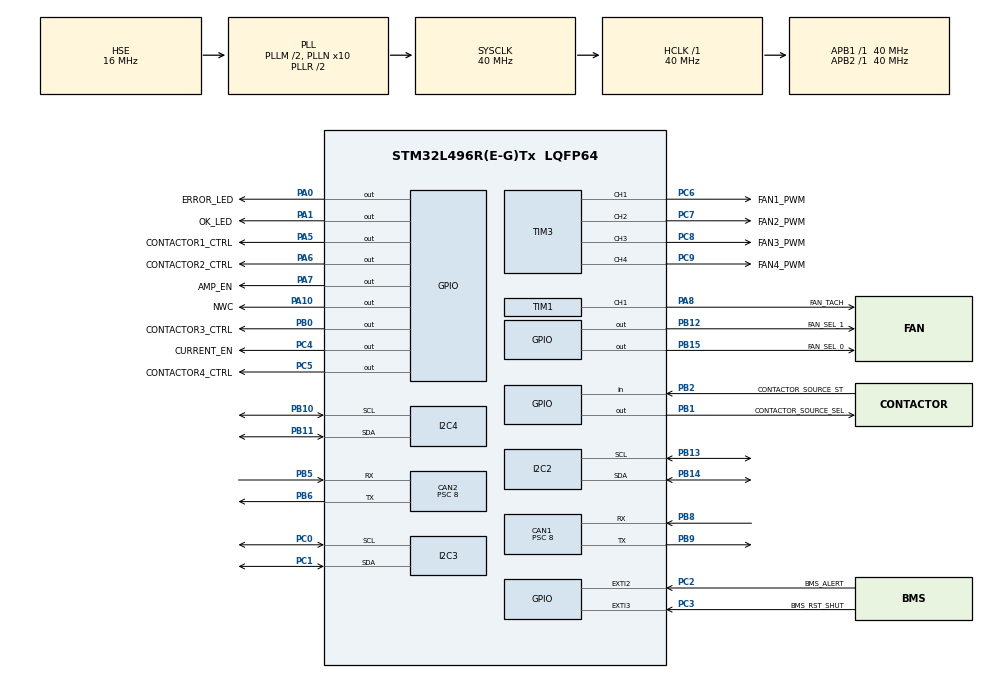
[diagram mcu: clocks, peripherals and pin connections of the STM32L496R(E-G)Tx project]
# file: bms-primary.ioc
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CAN1.BS1=CAN_BS1_8TQ
CAN1.BS2=CAN_BS2_1TQ
CAN1.CalculateBaudRate=500000
CAN1.CalculateTimeBit=2000
CAN1.CalculateTimeQuantum=200.0
CAN1.Prescaler=8
CAN2.BS1=CAN_BS1_8TQ
CAN2.BS2=CAN_BS2_1TQ
CAN2.CalculateBaudRate=500000
CAN2.CalculateTimeBit=2000
CAN2.CalculateTimeQuantum=200.0
CAN2.Prescaler=8
FREERTOS.Tasks01=defaultTask,24,128,StartDefaultTask,Default,NULL,Dynamic,NULL,NULL
I2C2.Timing=0x00909BEB
I2C3.Timing=0x00D09BE3
I2C4.Timing=0x00909BEB
IWDG.Prescaler=IWDG_PRESCALER_256
IWDG.Reload=125
IWDG.Window=125
Mcu.Family=STM32L4
Mcu.Name=STM32L496R(E-G)Tx
Mcu.Package=LQFP64
NVIC.CAN1_RX0_IRQn=true\:5\:0\:false\:false\:true\:true\:true\:true\:true
NVIC.CAN1_RX1_IRQn=true\:5\:0\:false\:false\:true\:true\:true\:true\:true
NVIC.CAN2_RX0_IRQn=true\:5\:0\:false\:false\:true\:true\:true\:true\:true
NVIC.CAN2_RX1_IRQn=true\:5\:0\:false\:false\:true\:true\:true\:true\:true
NVIC.PriorityGroup=NVIC_PRIORITYGROUP_4
NVIC.TIM1_TRG_COM_TIM17_IRQn=true\:15\:0\:false\:false\:true\:false\:false\:true\:true
NVIC.TimeBase=TIM1_TRG_COM_TIM17_IRQn
NVIC.TimeBaseIP=TIM17
PA0.GPIO_Label=ERROR_LED
PA0.Signal=GPIO_Output
PA1.GPIO_Label=OK_LED
PA1.Signal=GPIO_Output
PA10.GPIO_Label=NWC
PA10.Signal=GPIO_Output
PA13\ (JTMS/SWDIO).Mode=Trace_Asynchronous_SW
PA13\ (JTMS/SWDIO).Signal=SYS_JTMS-SWDIO
PA14\ (JTCK/SWCLK).Mode=Trace_Asynchronous_SW
PA14\ (JTCK/SWCLK).Signal=SYS_JTCK-SWCLK
PA5.GPIO_Label=CONTACTOR1_CTRL
PA5.Signal=GPIO_Output
PA6.GPIO_Label=CONTACTOR2_CTRL
PA6.Signal=GPIO_Output
PA7.GPIO_Label=AMP_EN
PA7.Signal=GPIO_Output
PA8.GPIO_Label=FAN_TACH
PA8.Signal=S_TIM1_CH1
PB0.GPIO_Label=CONTACTOR3_CTRL
PB0.Signal=GPIO_Output
PB1.GPIO_Label=CONTACTOR_SOURCE_SEL
PB1.Signal=GPIO_Output
PB10.Mode=I2C
PB10.Signal=I2C4_SCL
PB11.Mode=I2C
PB11.Signal=I2C4_SDA
PB12.GPIO_Label=FAN_SEL_1
PB12.Signal=GPIO_Output
PB13.Mode=I2C
PB13.Signal=I2C2_SCL
PB14.Mode=I2C
PB14.Signal=I2C2_SDA
PB15.GPIO_Label=FAN_SEL_0
PB15.Signal=GPIO_Output
PB2.GPIO_Label=CONTACTOR_SOURCE_ST
PB2.Signal=GPIO_Input
PB3\ (JTDO/TRACESWO).Mode=Trace_Asynchronous_SW
PB3\ (JTDO/TRACESWO).Signal=SYS_JTDO-SWO
PB5.Mode=CAN_Activate
PB5.Signal=CAN2_RX
PB6.Mode=CAN_Activate
PB6.Signal=CAN2_TX
PB8.Mode=CAN_Activate
PB8.Signal=CAN1_RX
PB9.Mode=CAN_Activate
PB9.Signal=CAN1_TX
PC0.Mode=I2C
PC0.Signal=I2C3_SCL
PC1.Mode=I2C
PC1.Signal=I2C3_SDA
PC2.GPIO_Label=BMS_ALERT
PC2.Signal=GPXTI2
PC3.GPIO_Label=BMS_RST_SHUT
PC3.Signal=GPXTI3
PC4.GPIO_Label=CURRENT_EN
PC4.Signal=GPIO_Output
PC5.GPIO_Label=CONTACTOR4_CTRL
PC5.Signal=GPIO_Output
PC6.GPIO_Label=FAN1_PWM
PC6.Signal=S_TIM3_CH1
PC7.GPIO_Label=FAN2_PWM
PC7.Signal=S_TIM3_CH2
PC8.GPIO_Label=FAN3_PWM
PC8.Signal=S_TIM3_CH3
PC9.GPIO_Label=FAN4_PWM
PC9.Signal=S_TIM3_CH4
PH0-OSC_IN\ (PH0).Mode=HSE-External-Oscillator
PH0-OSC_IN\ (PH0).Signal=RCC_OSC_IN
PH1-OSC_OUT\ (PH1).Mode=HSE-External-Oscillator
PH1-OSC_OUT\ (PH1).Signal=RCC_OSC_OUT
ProjectManager.HeapSize=0x200
ProjectManager.StackSize=0x400
ProjectManager.TargetToolchain=Makefile
RCC.ADCFreq_Value=48000000
RCC.AHBFreq_Value=40000000
RCC.APB1Freq_Value=40000000
RCC.APB1TimFreq_Value=40000000
RCC.APB2Freq_Value=40000000
RCC.APB2TimFreq_Value=40000000
RCC.CortexFreq_Value=40000000
RCC.HCLKFreq_Value=40000000
RCC.HSE_VALUE=16000000
RCC.HSI48_VALUE=48000000
RCC.HSI_VALUE=16000000
RCC.LSE_VALUE=32768
RCC.MSI_VALUE=4000000
RCC.PLLM=2
RCC.PLLN=10
RCC.PLLSAI1N=12
RCC.PLLSourceVirtual=RCC_PLLSOURCE_HSE
RCC.SYSCLKFreq_VALUE=40000000
RCC.SYSCLKSource=RCC_SYSCLKSOURCE_PLLCLK
RCC.USBFreq_Value=48000000
RCC.VCOOutputFreq_Value=80000000
SH.S_TIM1_CH1.0=TIM1_CH1,PWM Generation1 CH1
SH.S_TIM3_CH1.0=TIM3_CH1,PWM Generation1 CH1
SH.S_TIM3_CH2.0=TIM3_CH2,PWM Generation2 CH2
SH.S_TIM3_CH3.0=TIM3_CH3,PWM Generation3 CH3
SH.S_TIM3_CH4.0=TIM3_CH4,PWM Generation4 CH4
TIM1.Channel-Output\ Compare1\ CH1=TIM_CHANNEL_1
TIM1.Channel-PWM\ Generation1\ CH1=TIM_CHANNEL_1
TIM3.Channel-PWM\ Generation1\ CH1=TIM_CHANNEL_1
TIM3.Channel-PWM\ Generation2\ CH2=TIM_CHANNEL_2
TIM3.Channel-PWM\ Generation3\ CH3=TIM_CHANNEL_3
TIM3.Channel-PWM\ Generation4\ CH4=TIM_CHANNEL_4
VP_FREERTOS_VS_CMSIS_V2.Mode=CMSIS_V2
VP_IWDG_VS_IWDG.Mode=IWDG_Activate
VP_SYS_VS_tim17.Mode=TIM17
VP_TIM16_VS_ClockSourceINT.Mode=Enable_Timer
board=custom

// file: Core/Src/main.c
/* USER CODE BEGIN Header */
/**
  ******************************************************************************
  * @file           : main.c
  * @brief          : Main program body
  ******************************************************************************
  * @attention
  *
  * Copyright (c) 2023 STMicroelectronics.
  * All rights reserved.
  *
  * This software is licensed under terms that can be found in the LICENSE file
  * in the root directory of this software component.
  * If no LICENSE file comes with this software, it is provided AS-IS.
  *
  ******************************************************************************
  */
/* USER CODE END Header */
#include "main.h"
#include "cmsis_os.h"

CAN_HandleTypeDef hcan1;
CAN_HandleTypeDef hcan2;

I2C_HandleTypeDef hi2c2;
I2C_HandleTypeDef hi2c3;
I2C_HandleTypeDef hi2c4;

IWDG_HandleTypeDef hiwdg;

TIM_HandleTypeDef htim1;
TIM_HandleTypeDef htim3;
TIM_HandleTypeDef htim16;

/* Definitions for defaultTask */
osThreadId_t defaultTaskHandle;
const osThreadAttr_t defaultTask_attributes = {
  .name = "defaultTask",
  .stack_size = 128 * 4,
  .priority = (osPriority_t) osPriorityNormal,
};
/* USER CODE BEGIN PV */
uint32_t utick = 0;
/* USER CODE END PV */

void SystemClock_Config(void);
static void MX_GPIO_Init(void);
static void MX_CAN1_Init(void);
static void MX_CAN2_Init(void);
static void MX_TIM3_Init(void);
static void MX_I2C3_Init(void);
static void MX_TIM1_Init(void);
static void MX_I2C4_Init(void);
static void MX_I2C2_Init(void);
static void MX_TIM16_Init(void);
static void MX_IWDG_Init(void);
void StartDefaultTask(void *argument);

/* USER CODE BEGIN PFP */
void CPP_UserSetup(void);
/* USER CODE END PFP */

int main(void)
{

  /* MCU Configuration--------------------------------------------------------*/

  /* Reset of all peripherals, Initializes the Flash interface and the Systick. */
  HAL_Init();

  /* Configure the system clock */
  SystemClock_Config();

  /* USER CODE BEGIN SysInit */

  // Set timebase interrupt to a high priority to enable HAL_Delay() during initialization
  HAL_NVIC_SetPriority(TIM1_TRG_COM_TIM17_IRQn, 1U, 0U);
  __enable_irq();
  __set_BASEPRI(6);

  /* USER CODE END SysInit */

  /* Initialize all configured peripherals */
  MX_GPIO_Init();
  MX_CAN1_Init();
  MX_CAN2_Init();
  MX_TIM3_Init();
  MX_I2C3_Init();
  MX_TIM1_Init();
  MX_I2C4_Init();
  MX_I2C2_Init();
  MX_TIM16_Init();
  MX_IWDG_Init();
  /* USER CODE BEGIN 2 */
  CPP_UserSetup();

  // Change timebase priority back to normal
  HAL_NVIC_SetPriority(TIM1_TRG_COM_TIM17_IRQn, 15U, 0U);
  /* USER CODE END 2 */

  /* Init scheduler */
  osKernelInitialize();

  /* Create the thread(s) */
  /* creation of defaultTask */
  defaultTaskHandle = osThreadNew(StartDefaultTask, NULL, &defaultTask_attributes);

  /* Start scheduler */
  osKernelStart();

  /* We should never get here as control is now taken by the scheduler */

  /* Infinite loop */
  while (1)
  {

  }
}

void SystemClock_Config(void)
{
  RCC_OscInitTypeDef RCC_OscInitStruct = {0};
  RCC_ClkInitTypeDef RCC_ClkInitStruct = {0};

  /** Configure the main internal regulator output voltage
  */
  if (HAL_PWREx_ControlVoltageScaling(PWR_REGULATOR_VOLTAGE_SCALE1) != HAL_OK)
  {
    Error_Handler();
  }

  /** Initializes the RCC Oscillators according to the specified parameters
  * in the RCC_OscInitTypeDef structure.
  */
  RCC_OscInitStruct.OscillatorType = RCC_OSCILLATORTYPE_LSI|RCC_OSCILLATORTYPE_HSE;
  RCC_OscInitStruct.HSEState = RCC_HSE_ON;
  RCC_OscInitStruct.LSIState = RCC_LSI_ON;
  RCC_OscInitStruct.PLL.PLLState = RCC_PLL_ON;
  RCC_OscInitStruct.PLL.PLLSource = RCC_PLLSOURCE_HSE;
  RCC_OscInitStruct.PLL.PLLM = 2;
  RCC_OscInitStruct.PLL.PLLN = 10;
  RCC_OscInitStruct.PLL.PLLP = RCC_PLLP_DIV2;
  RCC_OscInitStruct.PLL.PLLQ = RCC_PLLQ_DIV2;
  RCC_OscInitStruct.PLL.PLLR = RCC_PLLR_DIV2;
  if (HAL_RCC_OscConfig(&RCC_OscInitStruct) != HAL_OK)
  {
    Error_Handler();
  }

  /** Initializes the CPU, AHB and APB buses clocks
  */
  RCC_ClkInitStruct.ClockType = RCC_CLOCKTYPE_HCLK|RCC_CLOCKTYPE_SYSCLK
                              |RCC_CLOCKTYPE_PCLK1|RCC_CLOCKTYPE_PCLK2;
  RCC_ClkInitStruct.SYSCLKSource = RCC_SYSCLKSOURCE_PLLCLK;
  RCC_ClkInitStruct.AHBCLKDivider = RCC_SYSCLK_DIV1;
  RCC_ClkInitStruct.APB1CLKDivider = RCC_HCLK_DIV1;
  RCC_ClkInitStruct.APB2CLKDivider = RCC_HCLK_DIV1;

  if (HAL_RCC_ClockConfig(&RCC_ClkInitStruct, FLASH_LATENCY_2) != HAL_OK)
  {
    Error_Handler();
  }
}

static void MX_CAN1_Init(void)
{

  hcan1.Instance = CAN1;
  hcan1.Init.Prescaler = 8;
  hcan1.Init.Mode = CAN_MODE_NORMAL;
  hcan1.Init.SyncJumpWidth = CAN_SJW_1TQ;
  hcan1.Init.TimeSeg1 = CAN_BS1_8TQ;
  hcan1.Init.TimeSeg2 = CAN_BS2_1TQ;
  hcan1.Init.TimeTriggeredMode = DISABLE;
  hcan1.Init.AutoBusOff = DISABLE;
  hcan1.Init.AutoWakeUp = DISABLE;
  hcan1.Init.AutoRetransmission = DISABLE;
  hcan1.Init.ReceiveFifoLocked = DISABLE;
  hcan1.Init.TransmitFifoPriority = DISABLE;
  if (HAL_CAN_Init(&hcan1) != HAL_OK)
  {
    Error_Handler();
  }

}

static void MX_CAN2_Init(void)
{

  hcan2.Instance = CAN2;
  hcan2.Init.Prescaler = 8;
  hcan2.Init.Mode = CAN_MODE_NORMAL;
  hcan2.Init.SyncJumpWidth = CAN_SJW_1TQ;
  hcan2.Init.TimeSeg1 = CAN_BS1_8TQ;
  hcan2.Init.TimeSeg2 = CAN_BS2_1TQ;
  hcan2.Init.TimeTriggeredMode = DISABLE;
  hcan2.Init.AutoBusOff = DISABLE;
  hcan2.Init.AutoWakeUp = DISABLE;
  hcan2.Init.AutoRetransmission = DISABLE;
  hcan2.Init.ReceiveFifoLocked = DISABLE;
  hcan2.Init.TransmitFifoPriority = DISABLE;
  if (HAL_CAN_Init(&hcan2) != HAL_OK)
  {
    Error_Handler();
  }

}

static void MX_I2C2_Init(void)
{

  hi2c2.Instance = I2C2;
  hi2c2.Init.Timing = 0x00909BEB;
  hi2c2.Init.OwnAddress1 = 0;
  hi2c2.Init.AddressingMode = I2C_ADDRESSINGMODE_7BIT;
  hi2c2.Init.DualAddressMode = I2C_DUALADDRESS_DISABLE;
  hi2c2.Init.OwnAddress2 = 0;
  hi2c2.Init.OwnAddress2Masks = I2C_OA2_NOMASK;
  hi2c2.Init.GeneralCallMode = I2C_GENERALCALL_DISABLE;
  hi2c2.Init.NoStretchMode = I2C_NOSTRETCH_DISABLE;
  if (HAL_I2C_Init(&hi2c2) != HAL_OK)
  {
    Error_Handler();
  }

  /** Configure Analogue filter
  */
  if (HAL_I2CEx_ConfigAnalogFilter(&hi2c2, I2C_ANALOGFILTER_ENABLE) != HAL_OK)
  {
    Error_Handler();
  }

  /** Configure Digital filter
  */
  if (HAL_I2CEx_ConfigDigitalFilter(&hi2c2, 0) != HAL_OK)
  {
    Error_Handler();
  }

}

static void MX_I2C3_Init(void)
{

  hi2c3.Instance = I2C3;
  hi2c3.Init.Timing = 0x00D09BE3;
  hi2c3.Init.OwnAddress1 = 0;
  hi2c3.Init.AddressingMode = I2C_ADDRESSINGMODE_7BIT;
  hi2c3.Init.DualAddressMode = I2C_DUALADDRESS_DISABLE;
  hi2c3.Init.OwnAddress2 = 0;
  hi2c3.Init.OwnAddress2Masks = I2C_OA2_NOMASK;
  hi2c3.Init.GeneralCallMode = I2C_GENERALCALL_DISABLE;
  hi2c3.Init.NoStretchMode = I2C_NOSTRETCH_DISABLE;
  if (HAL_I2C_Init(&hi2c3) != HAL_OK)
  {
    Error_Handler();
  }

  /** Configure Analogue filter
  */
  if (HAL_I2CEx_ConfigAnalogFilter(&hi2c3, I2C_ANALOGFILTER_ENABLE) != HAL_OK)
  {
    Error_Handler();
  }

  /** Configure Digital filter
  */
  if (HAL_I2CEx_ConfigDigitalFilter(&hi2c3, 0) != HAL_OK)
  {
    Error_Handler();
  }

}

static void MX_I2C4_Init(void)
{

  hi2c4.Instance = I2C4;
  hi2c4.Init.Timing = 0x00909BEB;
  hi2c4.Init.OwnAddress1 = 0;
  hi2c4.Init.AddressingMode = I2C_ADDRESSINGMODE_7BIT;
  hi2c4.Init.DualAddressMode = I2C_DUALADDRESS_DISABLE;
  hi2c4.Init.OwnAddress2 = 0;
  hi2c4.Init.OwnAddress2Masks = I2C_OA2_NOMASK;
  hi2c4.Init.GeneralCallMode = I2C_GENERALCALL_DISABLE;
  hi2c4.Init.NoStretchMode = I2C_NOSTRETCH_DISABLE;
  if (HAL_I2C_Init(&hi2c4) != HAL_OK)
  {
    Error_Handler();
  }

  /** Configure Analogue filter
  */
  if (HAL_I2CEx_ConfigAnalogFilter(&hi2c4, I2C_ANALOGFILTER_ENABLE) != HAL_OK)
  {
    Error_Handler();
  }

  /** Configure Digital filter
  */
  if (HAL_I2CEx_ConfigDigitalFilter(&hi2c4, 0) != HAL_OK)
  {
    Error_Handler();
  }

}

static void MX_IWDG_Init(void)
{

  hiwdg.Instance = IWDG;
  hiwdg.Init.Prescaler = IWDG_PRESCALER_256;
  hiwdg.Init.Window = 125;
  hiwdg.Init.Reload = 125;
  if (HAL_IWDG_Init(&hiwdg) != HAL_OK)
  {
    Error_Handler();
  }

}

static void MX_TIM1_Init(void)
{

  TIM_MasterConfigTypeDef sMasterConfig = {0};
  TIM_OC_InitTypeDef sConfigOC = {0};
  TIM_BreakDeadTimeConfigTypeDef sBreakDeadTimeConfig = {0};

  htim1.Instance = TIM1;
  htim1.Init.Prescaler = 0;
  htim1.Init.CounterMode = TIM_COUNTERMODE_UP;
  htim1.Init.Period = 65535;
  htim1.Init.ClockDivision = TIM_CLOCKDIVISION_DIV1;
  htim1.Init.RepetitionCounter = 0;
  htim1.Init.AutoReloadPreload = TIM_AUTORELOAD_PRELOAD_DISABLE;
  if (HAL_TIM_PWM_Init(&htim1) != HAL_OK)
  {
    Error_Handler();
  }
  sMasterConfig.MasterOutputTrigger = TIM_TRGO_RESET;
  sMasterConfig.MasterOutputTrigger2 = TIM_TRGO2_RESET;
  sMasterConfig.MasterSlaveMode = TIM_MASTERSLAVEMODE_DISABLE;
  if (HAL_TIMEx_MasterConfigSynchronization(&htim1, &sMasterConfig) != HAL_OK)
  {
    Error_Handler();
  }
  sConfigOC.OCMode = TIM_OCMODE_PWM1;
  sConfigOC.Pulse = 0;
  sConfigOC.OCPolarity = TIM_OCPOLARITY_HIGH;
  sConfigOC.OCNPolarity = TIM_OCNPOLARITY_HIGH;
  sConfigOC.OCFastMode = TIM_OCFAST_DISABLE;
  sConfigOC.OCIdleState = TIM_OCIDLESTATE_RESET;
  sConfigOC.OCNIdleState = TIM_OCNIDLESTATE_RESET;
  if (HAL_TIM_PWM_ConfigChannel(&htim1, &sConfigOC, TIM_CHANNEL_1) != HAL_OK)
  {
    Error_Handler();
  }
  sBreakDeadTimeConfig.OffStateRunMode = TIM_OSSR_DISABLE;
  sBreakDeadTimeConfig.OffStateIDLEMode = TIM_OSSI_DISABLE;
  sBreakDeadTimeConfig.LockLevel = TIM_LOCKLEVEL_OFF;
  sBreakDeadTimeConfig.DeadTime = 0;
  sBreakDeadTimeConfig.BreakState = TIM_BREAK_DISABLE;
  sBreakDeadTimeConfig.BreakPolarity = TIM_BREAKPOLARITY_HIGH;
  sBreakDeadTimeConfig.BreakFilter = 0;
  sBreakDeadTimeConfig.Break2State = TIM_BREAK2_DISABLE;
  sBreakDeadTimeConfig.Break2Polarity = TIM_BREAK2POLARITY_HIGH;
  sBreakDeadTimeConfig.Break2Filter = 0;
  sBreakDeadTimeConfig.AutomaticOutput = TIM_AUTOMATICOUTPUT_DISABLE;
  if (HAL_TIMEx_ConfigBreakDeadTime(&htim1, &sBreakDeadTimeConfig) != HAL_OK)
  {
    Error_Handler();
  }
  HAL_TIM_MspPostInit(&htim1);

}

static void MX_TIM3_Init(void)
{

  TIM_MasterConfigTypeDef sMasterConfig = {0};
  TIM_OC_InitTypeDef sConfigOC = {0};

  htim3.Instance = TIM3;
  htim3.Init.Prescaler = 0;
  htim3.Init.CounterMode = TIM_COUNTERMODE_UP;
  htim3.Init.Period = 65535;
  htim3.Init.ClockDivision = TIM_CLOCKDIVISION_DIV1;
  htim3.Init.AutoReloadPreload = TIM_AUTORELOAD_PRELOAD_DISABLE;
  if (HAL_TIM_PWM_Init(&htim3) != HAL_OK)
  {
    Error_Handler();
  }
  sMasterConfig.MasterOutputTrigger = TIM_TRGO_RESET;
  sMasterConfig.MasterSlaveMode = TIM_MASTERSLAVEMODE_DISABLE;
  if (HAL_TIMEx_MasterConfigSynchronization(&htim3, &sMasterConfig) != HAL_OK)
  {
    Error_Handler();
  }
  sConfigOC.OCMode = TIM_OCMODE_PWM1;
  sConfigOC.Pulse = 0;
  sConfigOC.OCPolarity = TIM_OCPOLARITY_HIGH;
  sConfigOC.OCFastMode = TIM_OCFAST_DISABLE;
  if (HAL_TIM_PWM_ConfigChannel(&htim3, &sConfigOC, TIM_CHANNEL_1) != HAL_OK)
  {
    Error_Handler();
  }
  if (HAL_TIM_PWM_ConfigChannel(&htim3, &sConfigOC, TIM_CHANNEL_2) != HAL_OK)
  {
    Error_Handler();
  }
  if (HAL_TIM_PWM_ConfigChannel(&htim3, &sConfigOC, TIM_CHANNEL_3) != HAL_OK)
  {
    Error_Handler();
  }
  if (HAL_TIM_PWM_ConfigChannel(&htim3, &sConfigOC, TIM_CHANNEL_4) != HAL_OK)
  {
    Error_Handler();
  }
  HAL_TIM_MspPostInit(&htim3);

}

static void MX_TIM16_Init(void)
{

  htim16.Instance = TIM16;
  htim16.Init.Prescaler = 0;
  htim16.Init.CounterMode = TIM_COUNTERMODE_UP;
  htim16.Init.Period = 65535;
  htim16.Init.ClockDivision = TIM_CLOCKDIVISION_DIV1;
  htim16.Init.RepetitionCounter = 0;
  htim16.Init.AutoReloadPreload = TIM_AUTORELOAD_PRELOAD_DISABLE;
  if (HAL_TIM_Base_Init(&htim16) != HAL_OK)
  {
    Error_Handler();
  }

}

static void MX_GPIO_Init(void)
{
  GPIO_InitTypeDef GPIO_InitStruct = {0};

  /* GPIO Ports Clock Enable */
  __HAL_RCC_GPIOH_CLK_ENABLE();
  __HAL_RCC_GPIOC_CLK_ENABLE();
  __HAL_RCC_GPIOA_CLK_ENABLE();
  __HAL_RCC_GPIOB_CLK_ENABLE();

  /*Configure GPIO pin Output Level */
  HAL_GPIO_WritePin(GPIOA, ERROR_LED_Pin|OK_LED_Pin|CONTACTOR1_CTRL_Pin|CONTACTOR2_CTRL_Pin
                          |AMP_EN_Pin|NWC_Pin, GPIO_PIN_RESET);

  /*Configure GPIO pin Output Level */
  HAL_GPIO_WritePin(GPIOC, CURRENT_EN_Pin|CONTACTOR4_CTRL_Pin, GPIO_PIN_RESET);

  /*Configure GPIO pin Output Level */
  HAL_GPIO_WritePin(GPIOB, CONTACTOR3_CTRL_Pin|CONTACTOR_SOURCE_SEL_Pin|FAN_SEL_1_Pin|FAN_SEL_0_Pin, GPIO_PIN_RESET);

  /*Configure GPIO pins : BMS_ALERT_Pin BMS_RST_SHUT_Pin */
  GPIO_InitStruct.Pin = BMS_ALERT_Pin|BMS_RST_SHUT_Pin;
  GPIO_InitStruct.Mode = GPIO_MODE_IT_RISING;
  GPIO_InitStruct.Pull = GPIO_NOPULL;
  HAL_GPIO_Init(GPIOC, &GPIO_InitStruct);

  /*Configure GPIO pins : ERROR_LED_Pin OK_LED_Pin CONTACTOR1_CTRL_Pin CONTACTOR2_CTRL_Pin
                           AMP_EN_Pin NWC_Pin */
  GPIO_InitStruct.Pin = ERROR_LED_Pin|OK_LED_Pin|CONTACTOR1_CTRL_Pin|CONTACTOR2_CTRL_Pin
                          |AMP_EN_Pin|NWC_Pin;
  GPIO_InitStruct.Mode = GPIO_MODE_OUTPUT_PP;
  GPIO_InitStruct.Pull = GPIO_NOPULL;
  GPIO_InitStruct.Speed = GPIO_SPEED_FREQ_LOW;
  HAL_GPIO_Init(GPIOA, &GPIO_InitStruct);

  /*Configure GPIO pins : CURRENT_EN_Pin CONTACTOR4_CTRL_Pin */
  GPIO_InitStruct.Pin = CURRENT_EN_Pin|CONTACTOR4_CTRL_Pin;
  GPIO_InitStruct.Mode = GPIO_MODE_OUTPUT_PP;
  GPIO_InitStruct.Pull = GPIO_NOPULL;
  GPIO_InitStruct.Speed = GPIO_SPEED_FREQ_LOW;
  HAL_GPIO_Init(GPIOC, &GPIO_InitStruct);

  /*Configure GPIO pins : CONTACTOR3_CTRL_Pin CONTACTOR_SOURCE_SEL_Pin FAN_SEL_1_Pin FAN_SEL_0_Pin */
  GPIO_InitStruct.Pin = CONTACTOR3_CTRL_Pin|CONTACTOR_SOURCE_SEL_Pin|FAN_SEL_1_Pin|FAN_SEL_0_Pin;
  GPIO_InitStruct.Mode = GPIO_MODE_OUTPUT_PP;
  GPIO_InitStruct.Pull = GPIO_NOPULL;
  GPIO_InitStruct.Speed = GPIO_SPEED_FREQ_LOW;
  HAL_GPIO_Init(GPIOB, &GPIO_InitStruct);

  /*Configure GPIO pin : CONTACTOR_SOURCE_ST_Pin */
  GPIO_InitStruct.Pin = CONTACTOR_SOURCE_ST_Pin;
  GPIO_InitStruct.Mode = GPIO_MODE_INPUT;
  GPIO_InitStruct.Pull = GPIO_NOPULL;
  HAL_GPIO_Init(CONTACTOR_SOURCE_ST_GPIO_Port, &GPIO_InitStruct);

}

void StartDefaultTask(void *argument)
{
  for(;;)
  {
    osDelay(1);
  }
}

void HAL_TIM_PeriodElapsedCallback(TIM_HandleTypeDef *htim)
{
  if (htim->Instance == TIM17) {
    HAL_IncTick();
  }
}

void Error_Handler(void)
{
  __disable_irq();
  while (1)
  {
  }
}
